# HC32F155 register map
File version: 1.0
CPU: CM0+ r0p1, little endian, no MPU, no FPU, 2 interrupt priority bits
Registers are 32-bit, read-write, reset 0x0 unless marked. A register's access mark holds for its fields unless they carry their own. Offsets are from the block's base; [hi:lo] are bit positions; {n}, {i} and the like mark numbered series; 'fields as' and 'values as' point back to an identical list.

## DBGC_T
Base 0xE0042000
{0x0+4i} AUTHID{i} (i=0..2)
0x0C RESV0
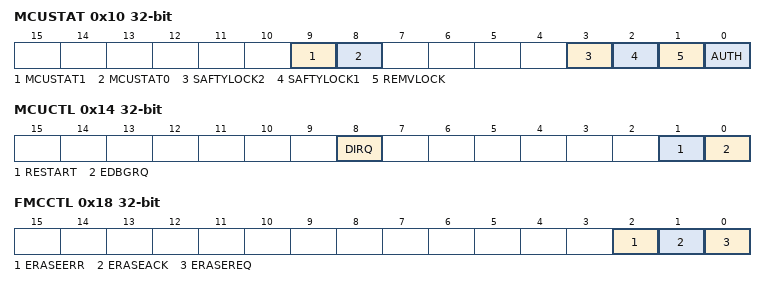
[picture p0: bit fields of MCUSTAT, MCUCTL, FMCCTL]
0x10 MCUSTAT
  [9] MCUSTAT1, [8] MCUSTAT0, [3] SAFTYLOCK2, [2] SAFTYLOCK1, [1] REMVLOCK, [0] AUTH
0x14 MCUCTL
  [8] DIRQ, [1] RESTART, [0] EDBGRQ
0x18 FMCCTL
  [2] ERASEERR, [1] ERASEACK, [0] ERASEREQ

## DMA
Base 0x40013000
0x00 EN
  [0] EN
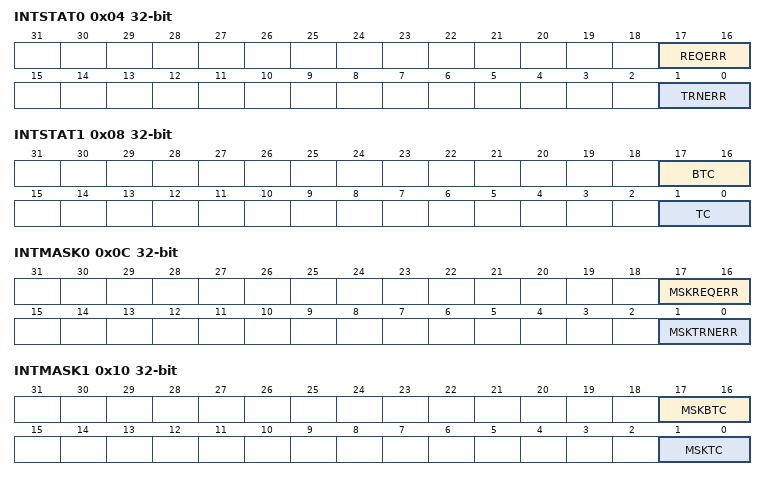
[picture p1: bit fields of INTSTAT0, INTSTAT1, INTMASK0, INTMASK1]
0x04 INTSTAT0 ro
  [17:16] REQERR, [1:0] TRNERR
0x08 INTSTAT1 ro
  [17:16] BTC, [1:0] TC
0x0C INTMASK0
  [17:16] MSKREQERR, [1:0] MSKTRNERR
0x10 INTMASK1
  [17:16] MSKBTC, [1:0] MSKTC
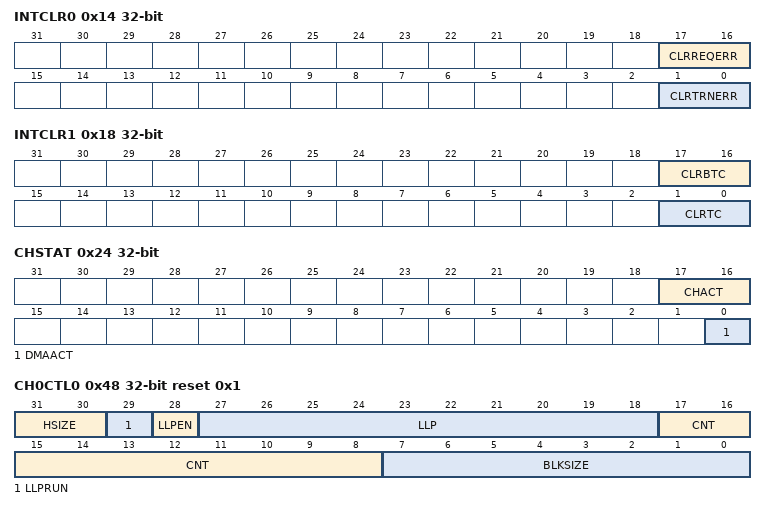
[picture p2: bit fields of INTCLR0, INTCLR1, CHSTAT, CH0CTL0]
0x14 INTCLR0 wo
  [17:16] CLRREQERR, [1:0] CLRTRNERR
0x18 INTCLR1 wo
  [17:16] CLRBTC, [1:0] CLRTC
0x1C CHEN
  [1:0] CHEN
0x24 CHSTAT ro
  [17:16] CHACT, [0] DMAACT
0x30 BASE1_LLP reset 0x20000000
  [31:14] LLP
0x34 BASE2_LLP
  [31:14] LLP
0x38 CHENCLR
  [1:0] CHENCLR
0x40 SAR0
0x44 DAR0
0x48 CH0CTL0 reset 0x1
  [31:30] HSIZE, [29] LLPRUN, [28] LLPEN, [27:18] LLP, [17:8] CNT, [7:0] BLKSIZE
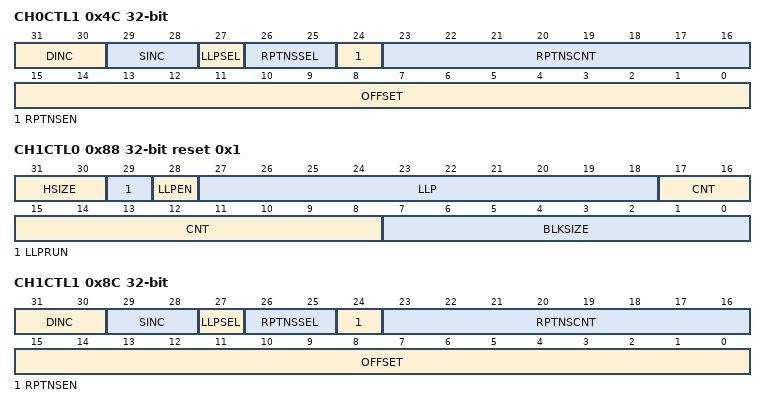
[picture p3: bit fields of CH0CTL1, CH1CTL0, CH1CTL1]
0x4C CH0CTL1
  [31:30] DINC, [29:28] SINC, [27] LLPSEL, [26:25] RPTNSSEL, [24] RPTNSEN, [23:16] RPTNSCNT, [15:0] OFFSET
0x80 SAR1
0x84 DAR1
0x88 CH1CTL0 reset 0x1
  fields as CH0CTL0
0x8C CH1CTL1
  fields as CH0CTL1

## EFM
Base 0x40000800
0x00 FAPRT
  [15:0] FAPRT
0x04 FSTP
  [0] FSTP
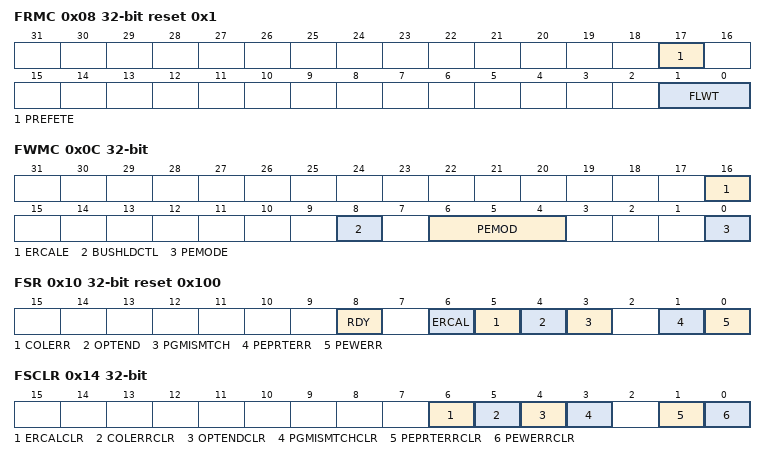
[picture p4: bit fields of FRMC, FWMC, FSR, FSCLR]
0x08 FRMC reset 0x1
  [17] PREFETE, [1:0] FLWT
0x0C FWMC
  [16] ERCALE, [8] BUSHLDCTL, [6:4] PEMOD, [0] PEMODE
0x10 FSR ro reset 0x100
  [8] RDY, [6] ERCAL, [5] COLERR, [4] OPTEND, [3] PGMISMTCH, [1] PEPRTERR, [0] PEWERR
0x14 FSCLR
  [6] ERCALCLR, [5] COLERRCLR, [4] OPTENDCLR, [3] PGMISMTCHCLR, [1] PEPRTERRCLR, [0] PEWERRCLR
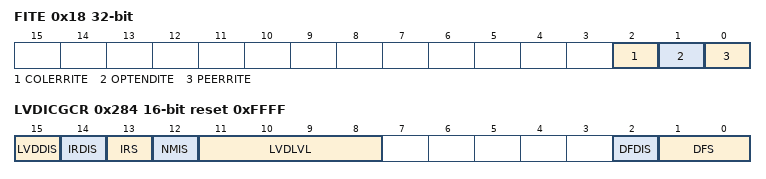
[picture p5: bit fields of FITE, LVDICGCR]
0x18 FITE
  [2] COLERRITE, [1] OPTENDITE, [0] PEERRITE
0x20 FPMTSW
  [17:0] FPMTSW
0x24 FPMTEW
  [17:0] FPMTEW
{0x50+4i} UQID{i} ro (i=0..2)
0x282 HRCCFGR 8-bit
  [3:0] HRCFREQS
0x284 LVDICGCR 16-bit reset 0xFFFF
  [15] LVDDIS, [14] IRDIS, [13] IRS, [12] NMIS, [11:8] LVDLVL, [2] DFDIS, [1:0] DFS

## GPIO
Base 0x40013800
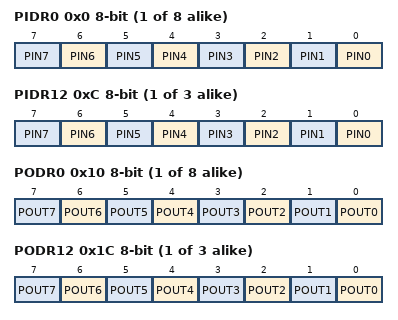
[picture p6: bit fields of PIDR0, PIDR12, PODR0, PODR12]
{0x0+i} PIDR{i} 8-bit ro (i=0..7)
  [n] PIN{n} (n=0..7)
{0x0+i} PIDR{i} 8-bit ro (i=12..14)
  [n] PIN{n} (n=0..7)
{0x10+i} PODR{i} 8-bit (i=0..7)
  [n] POUT{n} (n=0..7)
{0x10+i} PODR{i} 8-bit (i=12..14)
  [n] POUT{n} (n=0..7)
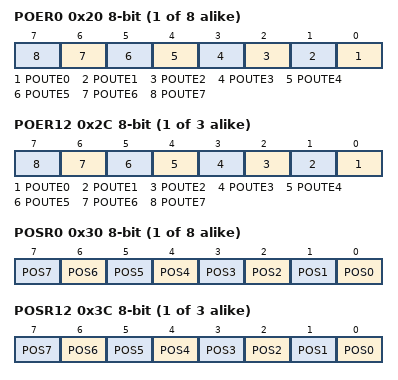
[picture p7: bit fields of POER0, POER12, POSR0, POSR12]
{0x20+i} POER{i} 8-bit (i=0..7)
  [n] POUTE{n} (n=0..7)
{0x20+i} POER{i} 8-bit (i=12..14)
  [n] POUTE{n} (n=0..7)
{0x30+i} POSR{i} 8-bit wo (i=0..7)
  [n] POS{n} (n=0..7)
{0x30+i} POSR{i} 8-bit wo (i=12..14)
  [n] POS{n} (n=0..7)
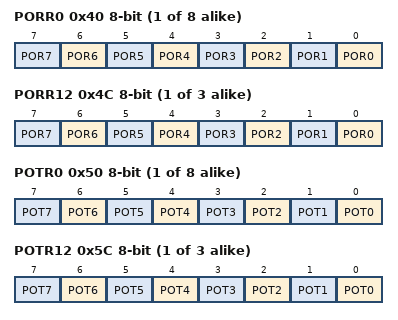
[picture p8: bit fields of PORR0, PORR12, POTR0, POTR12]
{0x40+i} PORR{i} 8-bit wo (i=0..7)
  [n] POR{n} (n=0..7)
{0x40+i} PORR{i} 8-bit wo (i=12..14)
  [n] POR{n} (n=0..7)
{0x50+i} POTR{i} 8-bit wo (i=0..7)
  [n] POT{n} (n=0..7)
{0x50+i} POTR{i} 8-bit wo (i=12..14)
  [n] POT{n} (n=0..7)
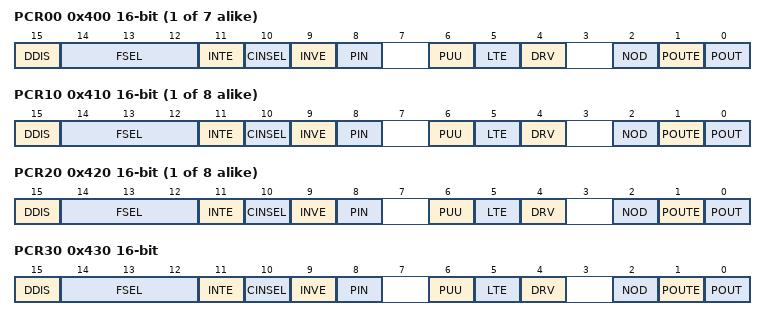
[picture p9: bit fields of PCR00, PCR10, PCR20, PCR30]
{0x400+2i} PCR{i:02} 16-bit (reset mask 0x7F77) (i=0..6)
  [15] DDIS, [14:12] FSEL, [11] INTE, [10] CINSEL, [9] INVE, [8] PIN ro, [6] PUU, [5] LTE, [4] DRV, [2] NOD, [1] POUTE, [0] POUT
{0x3FC+2i} PCR{i} 16-bit (reset mask 0x7F77) (i=10..17)
  fields as PCR00
{0x3F8+2i} PCR{i} 16-bit (reset mask 0x7F77) (i=20..27)
  fields as PCR00
0x430 PCR30 16-bit (reset mask 0x7F77)
  fields as PCR00
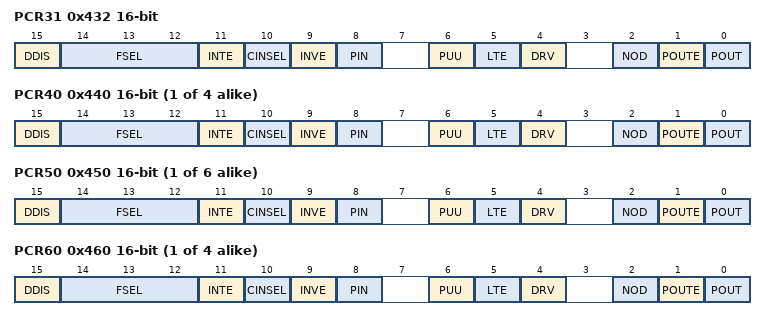
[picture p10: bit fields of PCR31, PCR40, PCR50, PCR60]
0x432 PCR31 16-bit (reset mask 0x7F77)
  fields as PCR00
{0x3F0+2i} PCR{i} 16-bit (reset mask 0x7F77) (i=40..43)
  fields as PCR00
{0x3EC+2i} PCR{i} 16-bit (reset mask 0x7F77) (i=50..55)
  fields as PCR00
{0x3E8+2i} PCR{i} 16-bit (reset mask 0x7F77) (i=60..63)
  fields as PCR00
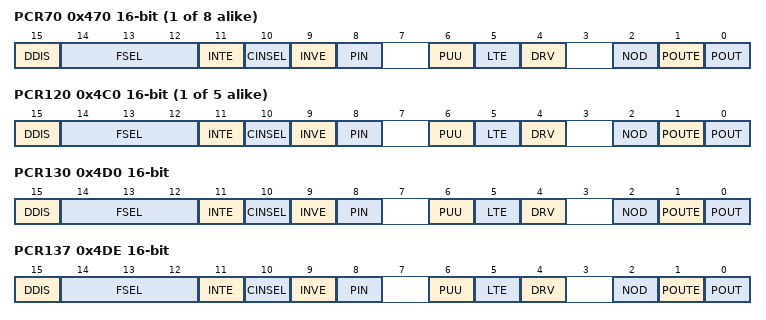
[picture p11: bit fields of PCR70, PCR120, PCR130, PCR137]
{0x3E4+2i} PCR{i} 16-bit (reset mask 0x7F77) (i=70..77)
  fields as PCR00
{0x3D0+2i} PCR{i} 16-bit (reset mask 0x7F77) (i=120..124)
  fields as PCR00
0x4D0 PCR130 16-bit (reset mask 0x7F77)
  fields as PCR00
0x4DE PCR137 16-bit (reset mask 0x7F77)
  fields as PCR00
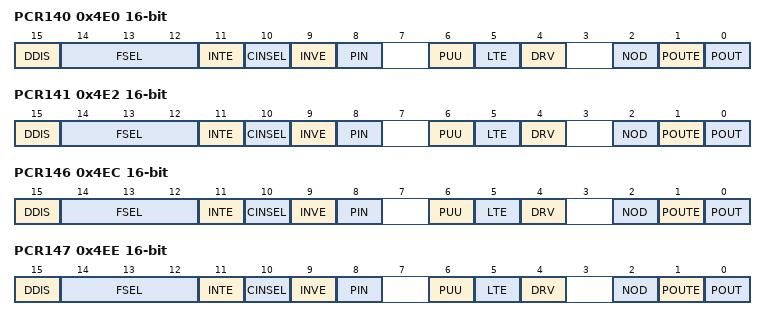
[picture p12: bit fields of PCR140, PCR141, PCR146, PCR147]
0x4E0 PCR140 16-bit (reset mask 0x7F77)
  fields as PCR00
0x4E2 PCR141 16-bit (reset mask 0x7F77)
  fields as PCR00
0x4EC PCR146 16-bit (reset mask 0x7F77)
  fields as PCR00
0x4EE PCR147 16-bit (reset mask 0x7F77)
  fields as PCR00
0x500 PSPCR 16-bit reset 0x3
  [1:0] SPFE
0x504 PCCR 16-bit reset 0x4000
  [15:14] RDWT
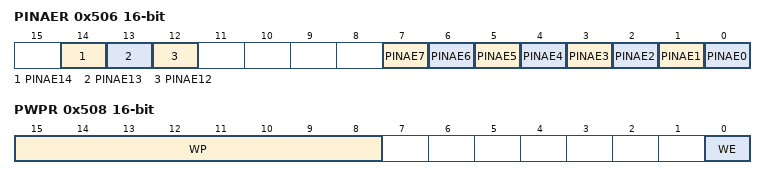
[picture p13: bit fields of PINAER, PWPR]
0x506 PINAER 16-bit
  [14] PINAE14, [13] PINAE13, [12] PINAE12, [n] PINAE{n} (n=0..7)
0x508 PWPR 16-bit
  [15:8] WP wo, [0] WE
